# DP32G030 register map
File version: 1.0
CPU: CM0 r0p0, little endian, no MPU, no FPU, 4 interrupt priority bits
Registers are 32-bit, read-write, reset 0x0 unless marked. A register's access mark holds for its fields unless they carry their own. Offsets are from the block's base; [hi:lo] are bit positions.

## PWM_PLUS1 — PWM_PLUS1 unit
Base 0x400B4800
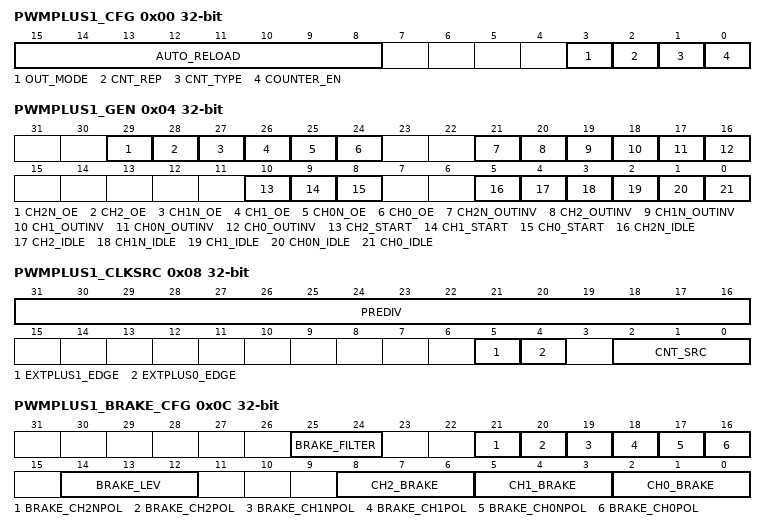
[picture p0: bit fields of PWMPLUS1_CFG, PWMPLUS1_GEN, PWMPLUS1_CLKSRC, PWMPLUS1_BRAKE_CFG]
0x00 PWMPLUS1_CFG
  [15:8] AUTO_RELOAD — Auto-Load Register, which indicates how many times after a cycle overflow the cycle value, compare value, deadband value and TRIGGER value are automatically loaded once. The autoload action performs an autoload after (AUTO_RELOAD+1) cycle overflow.
  [3] OUT_MODE — PWM output mode 0: Edge aligned mode output 1: Center-aligned mode output
  [2] CNT_REP — PWM Counter Cycle Method 0: Single, stop after one counting cycle 1: Loop, start and count in a loop until the software stops
  [1] CNT_TYPE — PWM Counter Behavior 0: count up 1: Counting down If center-aligned mode, it indicates the counting behavior of the first half cycle of the counter.
  [0] COUNTER_EN — Counter Enable Register When this bit is set to 1, it means that the counter starts counting, and CH0/CH1/CH2 generate the PWM output waveforms of the corresponding channels according to the pre-configured period value, comparison value and deadband value. When configured for the one-shot method, this bit is automatically cleared by the hardware after one clock cycle. When configured for cyclic mode, this bit needs to be cleared to zero by the software to stop the counter counting, and the output waveform level returns to the IDLE state after one full counting cycle.
0x04 PWMPLUS1_GEN
  [29] CH2N_OE — CH2N Channel waveform output enable 0: Output off, high resistance on pin 1: Output CH2N square wave
  [28] CH2_OE — CH2 Channel waveform output enable 0: Output off, high resistance on pin 1: Output CH2 square wave
  [27] CH1N_OE — CH1N Channel waveform output enable 0: Output off, high resistance on pin 1: Output CH1N square wave
  [26] CH1_OE — CH1 Channel waveform output enable 0: Output off, high resistance on pin 1: Output CH1 square wave
  [25] CH0N_OE — CH0N Channel waveform output enable 0: Output off, high resistance state on pin 1: Output CH0N square wave
  [24] CH0_OE — CH0 Channel waveform output enable 0: Output off, high resistance state on pin 1: Output CH0 square wave
  [21] CH2N_OUTINV — CH2N Channel Output Status Selection 0: No change in level 1: Output level reversal
  [20] CH2_OUTINV — CH2 Channel output state selection 0: No change in level 1: Output level reversal
  [19] CH1N_OUTINV — CH1N Channel output state selection 0: No change in level 1: Output level reversal
  [18] CH1_OUTINV — CH1 Channel output state selection 0: No change in level 1: Output level reversal
  [17] CH0N_OUTINV — CH0N Channel output state selection 0: No change in level 1: Output level reversal
  [16] CH0_OUTINV — CH0 Channel output state selection 0: No change in level 1: Output level reversal
  [10] CH2_START — Raw CH2 Output status value at start of channel counting 0: Raw CH2 channel output 0 level 1: The original CH2 channel outputs a level of 1. When counting starts, CH2N is the inverse of CH2.
  [9] CH1_START — Raw CH1 Output status value at start of channel counting 0: Raw CH1 channel output 0 level 1: The original CH1 channel outputs 1 level. After counting starts, CH1N is the inverse of CH1.
  [8] CH0_START — Output status value when raw CH0 channel starts counting 0: Raw CH0 channel output 0 level 1: The original CH0 channel outputs a level of 1. When counting starts, CH0N is the inverse of CH0.
  [5] CH2N_IDLE — Raw CH2N output status value when channel is idle 0: raw CH2N channel output 0 level 1: Raw CH2N channel output 1 level
  [4] CH2_IDLE — Raw CH2 Output status value when channel is idle 0: Raw CH2 channel output 0 level 1: Raw CH2 channel output 1 level
  [3] CH1N_IDLE — Raw CH1N Output status value when channel is idle 0: raw CH1N channel output 0 level 1: Raw CH1N channel output 1 level
  [2] CH1_IDLE — Raw CH1 Output status value when channel is idle 0: Raw CH1 channel output 0 level 1: Raw CH1 channel output 1 level
  [1] CH0N_IDLE — Raw CH0N Output status value when channel is idle 0: raw CH0N channel output 0 level 1: Raw CH0N channel output 1 level
  [0] CH0_IDLE — Raw CH0 Output status value when channel is idle 0: Raw CH0 channel output 0 level 1: Raw CH0 channel output 1 level
0x08 PWMPLUS1_CLKSRC
  [31:16] PREDIV — Internal prescaled clock frequency selection. Use the pclk of this module as the clock source of the prescaled clock. 0x0000: indicates 1 division of pclk 0x0001: Indicates the 2-division frequency of pclk. 0x0002: Indicates the 3-division frequency of pclk ...... 0xFFFF: indicates the 65536 division frequency of pclk
  [5] EXTPLUS1_EDGE — ExtPLUS1 Edge Selection Control for Count Clock 0: Falling edge trigger count 1: Rising edge trigger count
  [4] EXTPLUS0_EDGE — ExtPLUS0 Edge selection control when used as count clock 0: Falling edge trigger count 1: Rising edge trigger count
  [2:0] CNT_SRC — PWM Counter Count Clock Selection 000: Select internal pre-divided clock as count clock 001: Select extPLUS[0] as the count clock 010: Select extPLUS[1] as the count clock 011: Select tmPLUS[0] as the count clock 100: Select tmPLUS[1] as count clock 101: Select tmPLUS[2] as count clock 110: Select tmPLUS[3] as the count clock
0x0C PWMPLUS1_BRAKE_CFG
  [25:24] BRAKE_FILTER — Digital filtering control of brake signals 00: No filtering 01: 2 internal pre-scaler clock filters performed 10: 4 internal pre-scaler clock filters performed 11: 8 internal pre-scaler clock filtering
  [21] BRAKE_CH2NPOL — CH2N output level selection during braking 0: Output when braking 0 1: Output when braking 1
  [20] BRAKE_CH2POL — CH2 output level selection during braking 0: Output when braking 0 1: Output when braking 1
  [19] BRAKE_CH1NPOL — CH1N output level selection when braking 0: Output when braking 0 1: Output when braking 1
  [18] BRAKE_CH1POL — CH1 output level selection during braking 0: Output when braking 0 1: Output when braking 1
  [17] BRAKE_CH0NPOL — CH0N output level selection when braking 0: Output when braking 0 1: Output when braking 1
  [16] BRAKE_CH0POL — CH0 output level selection during braking 0: Output when braking 0 1: Output when braking 1
  [14:12] BRAKE_LEV — Brake effective level selection Bit2 of BRAKE_LEV corresponds to brakein[2], and Bit1 corresponds to brakein[1], Bit0 corresponds to brakein[0]. 0: Indicates that the brake input is active low 1: Indicates that the brake input is active high
  [8:6] CH2_BRAKE — CH2/CH2N Brake Control Selection Bit2 of CH2_BRAKE corresponds to brakein[2], and Bit1 corresponds to brakein[1], Bit0 corresponds to brakein[0]. 0: Indicates not controlled by brake signal 1: Indicates controlled by brake signal
  [5:3] CH1_BRAKE — CH1/CH1N Brake control selection Bit2 of CH1_BRAKE corresponds to brakein[2], Bit1 corresponds to brakein[1], Bit0 corresponds to brakein[0]. 0: Indicates not controlled by brake signal 1: Indicates controlled by brake signal
  [2:0] CH0_BRAKE — CH0/CH0N Brake control selection Bit2 of CH0_BRAKE corresponds to brakein[2], Bit1 corresponds to brakein[1], Bit0 corresponds to brakein[0]. 0: Indicates not controlled by brake signal 1: Indicates controlled by brake signal
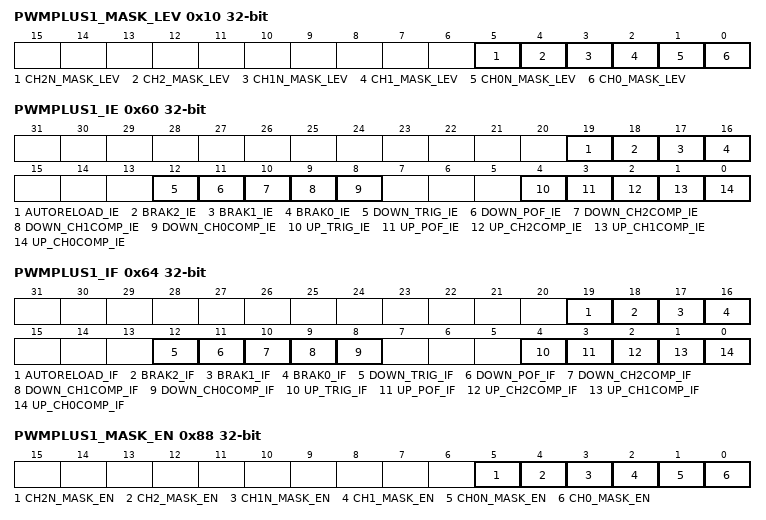
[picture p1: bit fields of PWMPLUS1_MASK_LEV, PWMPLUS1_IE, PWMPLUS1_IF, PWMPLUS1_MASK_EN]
0x10 PWMPLUS1_MASK_LEV
  [5] CH2N_MASK_LEV — CH2N Channel Mask Level Selection 0: Masking period forced output 0 1: Masking period mandatory output 1
  [4] CH2_MASK_LEV — CH2 Channel Mask Level Selection 0: Masking period forced output 0 1: Masking period mandatory output 1
  [3] CH1N_MASK_LEV — CH1N Channel Mask Level Selection 0: Masking period forced output 0 1: Masking period mandatory output 1
  [2] CH1_MASK_LEV — CH1 Channel Mask Level Selection 0: Masking period forced output 0 1: Masking period mandatory output 1
  [1] CH0N_MASK_LEV — CH0N Channel Mask Level Selection 0: Masking period forced output 0 1: Masking period mandatory output 1
  [0] CH0_MASK_LEV — CH0 Channel Mask Level Selection 0: Masking period forced output 0 1: Masking period mandatory output 1
0x1C PWMPLUS1_PERIOD reset 0xFFFF
  [15:0] PERIOD — PWMPLUS Cycle Configuration Register. The actual counting period is the value of the period configured for this register plus 1. Note 0: The period cannot be configured as 0. For example, if the configuration is decimal 199, the PWM waveform period is considered to be 200. NOTE 1: In center-aligned mode, the actual period is 2 times the configured value plus 1.
0x20 PWMPLUS1_CH0_COMP
  [15:0] CH0_COMP — CH0/CH0N Flip Point Configuration Register. Note: If the count value is less than the flip-point value, output start[0]; if it is greater than or equal to the flip-point value, output start[0] not.
0x24 PWMPLUS1_CH1_COMP
  [15:0] CH1_COMP — CH1/CH1N Flip Point Configuration Register. Note: If the count value is less than the flip point value, output start[1]; if it is greater than or equal to the flip point value, output start[1] not.
0x28 PWMPLUS1_CH2_COMP
  [15:0] CH2_COMP — CH2/CH2N Flip Point Configuration Register. Note: If the count value is less than the flip point value, output start[2]; if it is greater than or equal to the flip point value, output start[2] not.
0x30 PWMPLUS1_CH0_DT
  [9:0] CH0_DT — CH0/CH0N Deadband Length Configuration Registers Note 0: A configuration of 0 means no deadband; a configuration of 1 means a deadband length of 1, a configuration of 2 means a deadband length of 2, and so on. Note 1: When configuring this value, it is necessary to match with the cycle value, CH0_START value and CH0_COMP value, otherwise the output waveform may not achieve the expected effect.
0x34 PWMPLUS1_CH1_DT
  [9:0] CH1_DT — CH1/CH1N Deadband Length Configuration Registers Note 0: A configuration of 0 means no deadband; a configuration of 1 means a deadband length of 1, a configuration of 2 means a deadband length of 2, and so on. Note 1: When configuring this value, it is necessary to match with the period value, CH1_START value and CH1_COMP value, otherwise the output waveform may not achieve the expected effect.
0x38 PWMPLUS1_CH2_DT
  [9:0] CH2_DT — CH2/CH2N Deadband Length Configuration Registers Note 0: A configuration of 0 means no deadband; a configuration of 1 means a deadband length of 1, a configuration of 2 means a deadband length of 2, and so on. Note 1: When configuring this value, it is necessary to match with the period value, CH2_START value and CH2_COMP value, otherwise the output waveform may not achieve the desired effect.
0x40 PWMPLUS1_TRIG_COMP
  [15:0] TRIG_COMP — Internal Trigger Point Configuration Register Note: The internal trigger point value must be less than the cycle value
0x44 PWMPLUS1_TRIG_CFG
  [3:0] TIRGOUT_L_SEL — Output trigger0 signal function selection 0000: No signal output; 0001: Up count cycle overflow point; 0010: Down count cycle overflow point; 0011: Up or down count cycle overflow point; 0100: CH0 Counts up the flip point; 0101: CH0 Count down the flip point; 0110: CH0 Flip point up or down; 0111: CH1 Counts up the flip point; 1000: CH1 Counts down the flip point; 1001: CH1 Flip point up or down; 1010: CH2 Up Count Flip Point; 1011: CH2 Count down flip point; 1100: CH2 Flip point up or down; 1101: Count up internal trigger points; 1110: Count down internal trigger points; 1111: Up or down internal trigger point;
0x60 PWMPLUS1_IE
  [19] AUTORELOAD_IE — Autoload Interrupt Enable
  [18] BRAK2_IE — Brake 2 Interrupt Enable
  [17] BRAK1_IE — Brake 1 Interrupt enable
  [16] BRAK0_IE — Brake 0 Interrupt enable
  [12] DOWN_TRIG_IE — Count down to TRIGGER Trigger Point Interrupt Enable
  [11] DOWN_POF_IE — Down count cycle overflow interrupt enable
  [10] DOWN_CH2COMP_IE — Count Down CH2 Reach Flip Point Interrupt Enable
  [9] DOWN_CH1COMP_IE — Count Down CH1 Reach Flip Point Interrupt Enable
  [8] DOWN_CH0COMP_IE — Count Down CH0 Reach Flip Point Interrupt Enable
  [4] UP_TRIG_IE — Count up to TRIGGER Trigger Point Interrupt Enable
  [3] UP_POF_IE — Up count cycle overflow interrupt enable
  [2] UP_CH2COMP_IE — Count Up CH2 Reach Flip Point Interrupt Enable
  [1] UP_CH1COMP_IE — Count Up CH1 Reach Flip Point Interrupt Enable
  [0] UP_CH0COMP_IE — Count Up CH0 Reach Flip Point Interrupt Enable
0x64 PWMPLUS1_IF
  [19] AUTORELOAD_IF write-1-clears — Auto Load Interrupt Status Write 1 Clear
  [18] BRAK2_IF write-1-clears — Brake 2 Interrupt status Write 1 Clear Note: This state is only generated if any channel is controlled by the Brake 2 signal.
  [17] BRAK1_IF write-1-clears — Brake 1 Interrupt status Write 1 Clear Note: This state is only generated if any channel is controlled by the Brake 1 signal.
  [16] BRAK0_IF write-1-clears — Brake 0 Interrupt status Write 1 Clear Note: This state is only generated if any channel is controlled by the Brake 0 signal.
  [12] DOWN_TRIG_IF — Count down to TRIGGER Trigger Point Interrupt Status Write 1 Zeroed Note: Edge-aligned mode, indicates that the internal trigger point is reached when configured for counting down; center-aligned mode, indicates that the internal trigger point is reached in the first half-cycle when configured for counting down or the internal trigger point is reached in the second half-cycle when configured for counting up
  [11] DOWN_POF_IF write-1-clears — Down Count Cycle Overflow Interrupt Status Write 1 Clear Note: Edge-aligned mode, indicates that the cycle overflow point is reached when configured for counting down; center-aligned mode, indicates that the cycle overflow point is reached in the first half-cycle when configured for counting down or in the second half-cycle when configured for counting up
  [10] DOWN_CH2COMP_IF write-1-clears — Count down CH2 Reach flip-flop interrupt status write 1 clear
  [9] DOWN_CH1COMP_IF write-1-clears — Count down CH1 Reach flip-flop interrupt status write 1 clear
  [8] DOWN_CH0COMP_IF write-1-clears — Count down CH0 Reach flip-flop interrupt status write 1 clear Note: Edge-aligned mode means that the flip point is reached when configured to count down; center-aligned mode means that the flip point is reached in the first half cycle when configured to count down or in the second half cycle when configured to count up. The other channel behaviors are the same.
  [4] UP_TRIG_IF — Count up to TRIGGER Trigger Point Interrupt Status Write 1 Zeroed Note: Edge-aligned mode means that the internal trigger point is reached when configured to count up; center-aligned mode means that the internal trigger point is reached in the first half-cycle when configured to count up or in the second half-cycle when configured to count down
  [3] UP_POF_IF write-1-clears — Up Count Cycle Overflow Interrupt Status Write 1 Clear Note: Edge-aligned mode means that the cycle overflow point is reached when configured for counting up; center-aligned mode means that the cycle overflow point is reached in the first half of the cycle when configured for counting up or in the second half of the cycle when configured for counting down
  [2] UP_CH2COMP_IF write-1-clears — Count up CH2 Reach flip-flop interrupt status write 1 clear
  [1] UP_CH1COMP_IF write-1-clears — Count up CH1 Reach flip-flop interrupt status write 1 clear
  [0] UP_CH0COMP_IF write-1-clears — Count up CH0 Reach flip-flop interrupt status write 1 clear Note: Edge-aligned mode means that the flip point is reached when configured to count up; center-aligned mode means that the flip point is reached in the first half-cycle when configured to count up or the flip point is reached in the second half-cycle when configured to count down. The other channel behaviors are the same.
0x84 PWMPLUS1_SWLOAD
  [0] SWLOAD — PWM Configuration Register Software LOAD Control Bit In this module, the eight registers PWM_PERIOD, PWM_CH0_COMP, PWM_CH1_COMP, PWM_CH2_COMP, PWM_CH0_DT, PWM_CH1_DT, PWM_CH2_DT, TRIG_COMP, PWM_CH0_DT, PWM_CH1_DT, PWM_CH2_DT, and TRIG_COMP are used. The memory has its own shadow register. After software writes a 1 to this bit, the latest values stored in these 8 registers will be used by the device at the end of the current cycle. load into their respective shadow registers and take effect on the next cycle.
0x88 PWMPLUS1_MASK_EN
  [5] CH2N_MASK_EN — CH2N Channel Mask Enable Writing this bit to 1 activates the forced output mask function, and the forced output level is selected via MASK_CFG.
  [4] CH2_MASK_EN — CH2 Channel Mask Enable Writing this bit to 1 activates the forced output mask function, and the forced output level is selected via MASK_CFG.
  [3] CH1N_MASK_EN — CH1N Channel Mask Enable Writing this bit to 1 activates the forced output mask function, and the forced output level is selected via MASK_CFG.
  [2] CH1_MASK_EN — CH1 Channel Mask Enable Writing this bit to 1 activates the forced output mask function, and the forced output level is selected via MASK_CFG.
  [1] CH0N_MASK_EN — CH0N Channel Mask Enable Writing this bit to 1 activates the forced output mask function, and the forced output level is selected via MASK_CFG.
  [0] CH0_MASK_EN — CH0 Channel Mask Enable Writing this bit to 1 activates the forced output mask function, and the forced output level is selected via MASK_CFG.
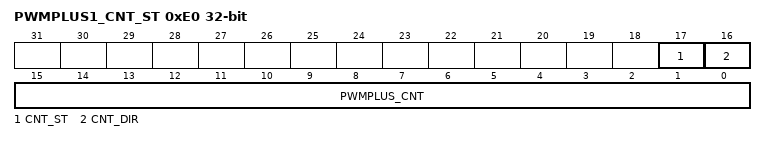
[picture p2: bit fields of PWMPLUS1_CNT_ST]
0xE0 PWMPLUS1_CNT_ST ro
  [17] CNT_ST — PWM Counter Operating Status 0: Indicates that the counter is not working 1: Indicates that the counter is counting
  [16] CNT_DIR — PWM Counter Current Count Direction 0: Indicates that the counter is currently counting up 1: Indicates that the counter is currently counting down
  [15:0] PWMPLUS_CNT — PWM Counter Current Count Value Register
0xE4 PWMPLUS1_BRAKE_ST ro
  [1:0] BRAKE_ST — Current status of brake input signal BRAKE_ST[1] corresponds to brake1 and BRAKE_ST[0] corresponds to brake0.
